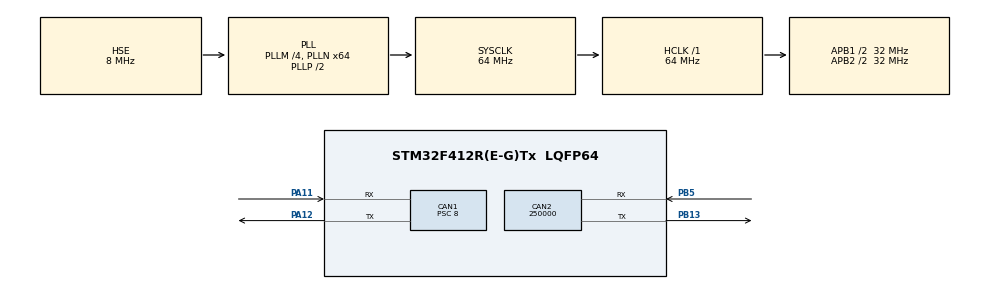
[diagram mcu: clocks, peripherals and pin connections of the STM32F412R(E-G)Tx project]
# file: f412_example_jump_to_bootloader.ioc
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CAN1.ABOM=ENABLE
CAN1.BS1=CAN_BS1_2TQ
CAN1.CalculateBaudRate=1000000
CAN1.CalculateTimeBit=1000
CAN1.CalculateTimeQuantum=250.0
CAN1.NART=ENABLE
CAN1.Prescaler=8
CAN2.ABOM=ENABLE
CAN2.BS1=CAN_BS1_2TQ
CAN2.BS2=CAN_BS2_5TQ
CAN2.CalculateBaudRate=250000
CAN2.CalculateTimeBit=4000
CAN2.CalculateTimeQuantum=500.0
CAN2.NART=ENABLE
Mcu.Family=STM32F4
Mcu.Name=STM32F412R(E-G)Tx
Mcu.Package=LQFP64
NVIC.CAN1_RX0_IRQn=true\:0\:0\:false\:false\:true\:true\:true\:true
NVIC.CAN2_RX1_IRQn=true\:0\:0\:false\:false\:true\:true\:true\:true
NVIC.PriorityGroup=NVIC_PRIORITYGROUP_4
PA11.Mode=CAN_Activate
PA11.Signal=CAN1_RX
PA12.Mode=CAN_Activate
PA12.Signal=CAN1_TX
PB13.Mode=CAN_Activate
PB13.Signal=CAN2_TX
PB5.Mode=CAN_Activate
PB5.Signal=CAN2_RX
PH0\ -\ OSC_IN.Mode=HSE-External-Oscillator
PH0\ -\ OSC_IN.Signal=RCC_OSC_IN
PH1\ -\ OSC_OUT.Mode=HSE-External-Oscillator
PH1\ -\ OSC_OUT.Signal=RCC_OSC_OUT
ProjectManager.HeapSize=0x200
ProjectManager.StackSize=0x400
ProjectManager.TargetToolchain=STM32CubeIDE
RCC.AHBFreq_Value=64000000
RCC.APB1CLKDivider=RCC_HCLK_DIV2
RCC.APB1Freq_Value=32000000
RCC.APB1TimFreq_Value=64000000
RCC.APB2CLKDivider=RCC_HCLK_DIV2
RCC.APB2Freq_Value=32000000
RCC.APB2TimFreq_Value=64000000
RCC.CortexFreq_Value=64000000
RCC.HCLKFreq_Value=64000000
RCC.HSE_VALUE=8000000
RCC.PLLI2SM=2
RCC.PLLI2SN=64
RCC.PLLM=4
RCC.PLLN=64
RCC.PLLSourceVirtual=RCC_PLLSOURCE_HSE
RCC.SYSCLKFreq_VALUE=64000000
RCC.SYSCLKSource=RCC_SYSCLKSOURCE_PLLCLK
RCC.USBFreq_Value=64000000
RCC.VCOOutputFreq_Value=128000000
board=custom

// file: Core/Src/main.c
/* USER CODE BEGIN Header */
/**
 ******************************************************************************
 * @file           : main.c
 * @brief          : Main program body
 ******************************************************************************
 * @attention
 *
 * Copyright (c) 2026 STMicroelectronics.
 * All rights reserved.
 *
 * This software is licensed under terms that can be found in the LICENSE file
 * in the root directory of this software component.
 * If no LICENSE file comes with this software, it is provided AS-IS.
 *
 ******************************************************************************
 */
/* USER CODE END Header */
#include "main.h"

CAN_HandleTypeDef hcan1;
CAN_HandleTypeDef hcan2;

void SystemClock_Config(void);
static void MX_GPIO_Init(void);
static void MX_CAN1_Init(void);
static void MX_CAN2_Init(void);

/* USER CODE BEGIN 0 */
extern volatile uint8_t triggerJumpToBootloader;
/* USER CODE END 0 */

int main(void) {

	/* MCU Configuration--------------------------------------------------------*/

	/* Reset of all peripherals, Initializes the Flash interface and the Systick. */
	HAL_Init();

	/* Configure the system clock */
	SystemClock_Config();

	/* Initialize all configured peripherals */
	MX_GPIO_Init();
	MX_CAN1_Init();
	MX_CAN2_Init();
	/* USER CODE BEGIN 2 */

	CAN_Setup_Bootloader_Jumper();

	/* USER CODE END 2 */

	/* Infinite loop */
	while (1) {
		if (triggerJumpToBootloader) {

			JumpToBootloader(); /* Agora em Thread Mode ✓ */
		}
	}
}

void SystemClock_Config(void) {
	RCC_OscInitTypeDef RCC_OscInitStruct = { 0 };
	RCC_ClkInitTypeDef RCC_ClkInitStruct = { 0 };

	/** Configure the main internal regulator output voltage
	 */
	__HAL_RCC_PWR_CLK_ENABLE();
	__HAL_PWR_VOLTAGESCALING_CONFIG(PWR_REGULATOR_VOLTAGE_SCALE1);

	/** Initializes the RCC Oscillators according to the specified parameters
	 * in the RCC_OscInitTypeDef structure.
	 */
	RCC_OscInitStruct.OscillatorType = RCC_OSCILLATORTYPE_HSE;
	RCC_OscInitStruct.HSEState = RCC_HSE_ON;
	RCC_OscInitStruct.PLL.PLLState = RCC_PLL_ON;
	RCC_OscInitStruct.PLL.PLLSource = RCC_PLLSOURCE_HSE;
	RCC_OscInitStruct.PLL.PLLM = 4;
	RCC_OscInitStruct.PLL.PLLN = 64;
	RCC_OscInitStruct.PLL.PLLP = RCC_PLLP_DIV2;
	RCC_OscInitStruct.PLL.PLLQ = 2;
	RCC_OscInitStruct.PLL.PLLR = 2;
	if (HAL_RCC_OscConfig(&RCC_OscInitStruct) != HAL_OK) {
		Error_Handler();
	}

	/** Initializes the CPU, AHB and APB buses clocks
	 */
	RCC_ClkInitStruct.ClockType = RCC_CLOCKTYPE_HCLK | RCC_CLOCKTYPE_SYSCLK
			| RCC_CLOCKTYPE_PCLK1 | RCC_CLOCKTYPE_PCLK2;
	RCC_ClkInitStruct.SYSCLKSource = RCC_SYSCLKSOURCE_PLLCLK;
	RCC_ClkInitStruct.AHBCLKDivider = RCC_SYSCLK_DIV1;
	RCC_ClkInitStruct.APB1CLKDivider = RCC_HCLK_DIV2;
	RCC_ClkInitStruct.APB2CLKDivider = RCC_HCLK_DIV2;

	if (HAL_RCC_ClockConfig(&RCC_ClkInitStruct, FLASH_LATENCY_1) != HAL_OK) {
		Error_Handler();
	}
}

static void MX_CAN1_Init(void) {

	hcan1.Instance = CAN1;
	hcan1.Init.Prescaler = 8;
	hcan1.Init.Mode = CAN_MODE_NORMAL;
	hcan1.Init.SyncJumpWidth = CAN_SJW_1TQ;
	hcan1.Init.TimeSeg1 = CAN_BS1_2TQ;
	hcan1.Init.TimeSeg2 = CAN_BS2_1TQ;
	hcan1.Init.TimeTriggeredMode = DISABLE;
	hcan1.Init.AutoBusOff = ENABLE;
	hcan1.Init.AutoWakeUp = DISABLE;
	hcan1.Init.AutoRetransmission = ENABLE;
	hcan1.Init.ReceiveFifoLocked = DISABLE;
	hcan1.Init.TransmitFifoPriority = DISABLE;
	if (HAL_CAN_Init(&hcan1) != HAL_OK) {
		Error_Handler();
	}

}

static void MX_CAN2_Init(void) {

	hcan2.Instance = CAN2;
	hcan2.Init.Prescaler = 16;
	hcan2.Init.Mode = CAN_MODE_NORMAL;
	hcan2.Init.SyncJumpWidth = CAN_SJW_1TQ;
	hcan2.Init.TimeSeg1 = CAN_BS1_2TQ;
	hcan2.Init.TimeSeg2 = CAN_BS2_5TQ;
	hcan2.Init.TimeTriggeredMode = DISABLE;
	hcan2.Init.AutoBusOff = ENABLE;
	hcan2.Init.AutoWakeUp = DISABLE;
	hcan2.Init.AutoRetransmission = ENABLE;
	hcan2.Init.ReceiveFifoLocked = DISABLE;
	hcan2.Init.TransmitFifoPriority = DISABLE;
	if (HAL_CAN_Init(&hcan2) != HAL_OK) {
		Error_Handler();
	}

}

static void MX_GPIO_Init(void) {

	/* GPIO Ports Clock Enable */
	__HAL_RCC_GPIOH_CLK_ENABLE();
	__HAL_RCC_GPIOB_CLK_ENABLE();
	__HAL_RCC_GPIOA_CLK_ENABLE();

}

void Error_Handler(void) {
	__disable_irq();
	while (1) {
	}
}
